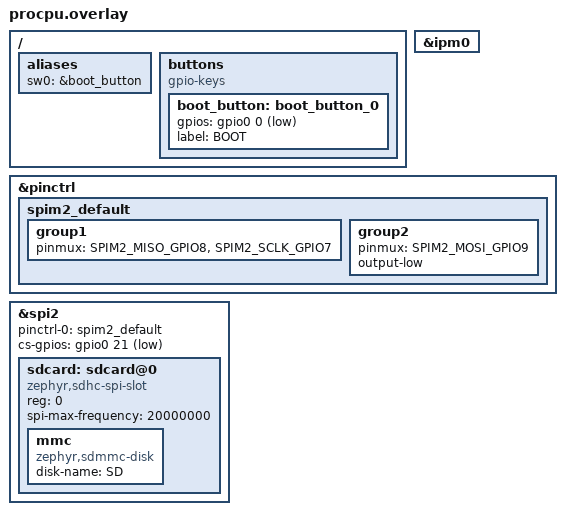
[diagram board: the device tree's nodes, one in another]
#include <zephyr/dt-bindings/pinctrl/esp-pinctrl-common.h>
#include <zephyr/dt-bindings/pinctrl/esp32s3-gpio-sigmap.h>
#include <zephyr/dt-bindings/pinctrl/esp32s3-pinctrl.h>

/* Enable IPM for PRO CPU ↔ APP CPU inter-processor communication */
&ipm0 {
	status = "okay";
};

/* SD card on SPI2 (XIAO ESP32S3 Sense wiring) — procpu-owned. */
&pinctrl {
	spim2_default: spim2_default {
		group1 {
			pinmux = <SPIM2_MISO_GPIO8>,
				 <SPIM2_SCLK_GPIO7>;
		};

		group2 {
			pinmux = <SPIM2_MOSI_GPIO9>;
			output-low;
		};
	};
};

&spi2 {
	status = "okay";
	#address-cells = <1>;
	#size-cells = <0>;
	pinctrl-0 = <&spim2_default>;
	pinctrl-names = "default";
	cs-gpios = <&gpio0 21 GPIO_ACTIVE_LOW>;

	sdcard: sdcard@0 {
		compatible = "zephyr,sdhc-spi-slot";
		reg = <0>;
		status = "okay";
		spi-max-frequency = <20000000>;

		mmc {
			compatible = "zephyr,sdmmc-disk";
			disk-name = "SD";
			status = "okay";
		};
	};
};

/*
 * BOOT button — GPIO0 (strapping pin, active-low, internal pull-up).
 * Used as the user record button until wake word (Milestone 5) replaces it.
 */
/ {
	aliases {
		sw0 = &boot_button;
	};

	buttons {
		compatible = "gpio-keys";
		boot_button: boot_button_0 {
			gpios = <&gpio0 0 (GPIO_PULL_UP | GPIO_ACTIVE_LOW)>;
			label = "BOOT";
		};
	};
};
